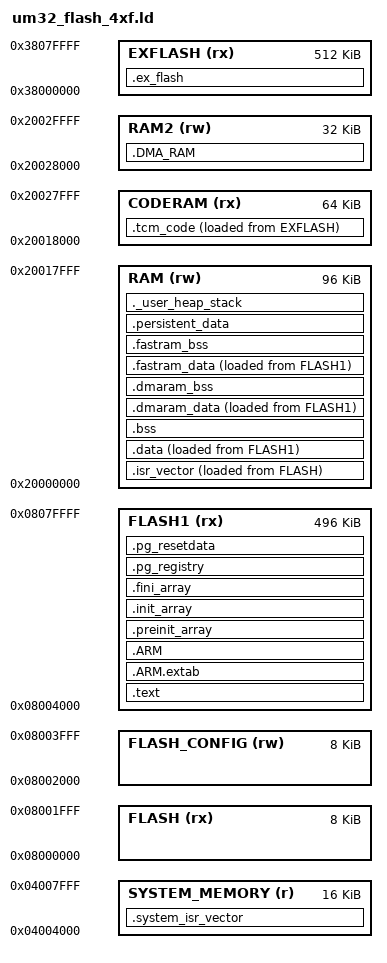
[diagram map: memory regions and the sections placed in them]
/*
*****************************************************************************
**
**  File        : um32_flash_4xf.ld
**
**  Abstract    : Linker script for UM324xF device with
**                512KByte eFLASH
**                128KByte SRAM0
**                32KByte  SRAM1
**                32KByte  SRAM2
**
*****************************************************************************
*/

/* Specify the memory areas. */
MEMORY
{
    FLASH (rx)        : ORIGIN = 0x08000000, LENGTH = 8K
    FLASH_CONFIG (rw) : ORIGIN = 0x08002000, LENGTH = 8K
    FLASH1 (rx)       : ORIGIN = 0x08004000, LENGTH = 496K
    EXFLASH (rx)      : ORIGIN = 0x38000000, LENGTH = 512K

    SYSTEM_MEMORY (r) : ORIGIN = 0x4004000, LENGTH = 16K

    RAM (rw)        : ORIGIN = 0x20000000, LENGTH = 96K
    CODERAM (rx)    : ORIGIN = 0x20018000, LENGTH = 64K
    RAM2 (rw)       : ORIGIN = 0x20028000, LENGTH = 32K
}

REGION_ALIAS("VECTAB", RAM)
REGION_ALIAS("FASTRAM", RAM)
REGION_ALIAS("STACKRAM", RAM)


/* Entry Point */
ENTRY(Reset_Handler)

/* Highest address of the user mode stack */
_Hot_Reboot_Flags_Size = 0;
_estack = ORIGIN(STACKRAM) + LENGTH(STACKRAM) - _Hot_Reboot_Flags_Size;    /* end of RAM */

/* Base address where the config is stored. */
__config_start = ORIGIN(FLASH_CONFIG);
__config_end = ORIGIN(FLASH_CONFIG) + LENGTH(FLASH_CONFIG);

/* Generate a link error if heap and stack don't fit into RAM */
_Min_Heap_Size = 0x100;       /* required amount of heap  */
_Min_Stack_Size = 0x800;      /* required amount of stack */

/* Define output sections */
SECTIONS
{
  /*
   * The ISR vector table is loaded at the beginning of the FLASH,
   * But it is linked (space reserved) at the beginning of the VECTAB region,
   * which is aliased either to FLASH or RAM.
   * When linked to RAM, the table can optionally be copied from FLASH to RAM
   * for table relocation.
   */

  _isr_vector_table_flash_base = LOADADDR(.isr_vector);
  PROVIDE (isr_vector_table_flash_base = _isr_vector_table_flash_base);

  .isr_vector :
  {
    . = ALIGN(512);
    PROVIDE (isr_vector_table_base = .);
    KEEP(*(.isr_vector)) /* Startup code */
    . = ALIGN(512);
    PROVIDE (isr_vector_table_end = .);
  } >VECTAB AT>FLASH

  /* System memory (read-only bootloader) interrupt vector */
  .system_isr_vector (NOLOAD) :
  {
    . = ALIGN(512);
    PROVIDE (system_isr_vector_table_base = .);
    KEEP(*(.system_isr_vector)) /* Bootloader code */
    . = ALIGN(512);
  } >SYSTEM_MEMORY

  /* The program code and other data goes into FLASH */
  .text :
  {
    . = ALIGN(4);
    *(.text)           /* .text sections (code) */
    *(.text*)          /* .text* sections (code) */
    *(.rodata)         /* .rodata sections (constants, strings, etc.) */
    *(.rodata*)        /* .rodata* sections (constants, strings, etc.) */
    *(.glue_7)         /* glue arm to thumb code */
    *(.glue_7t)        /* glue thumb to arm code */
    *(.eh_frame)

    KEEP (*(.init))
    KEEP (*(.fini))

    . = ALIGN(4);
    _etext = .;        /* define a global symbols at end of code */
  } >FLASH1

  .ARM.extab   : { *(.ARM.extab* .gnu.linkonce.armextab.*) } >FLASH1
    .ARM : {
      __exidx_start = .;
      *(.ARM.exidx*)
      __exidx_end = .;
    } >FLASH1

  .preinit_array     :
  {
    PROVIDE_HIDDEN (__preinit_array_start = .);
    KEEP (*(.preinit_array*))
    PROVIDE_HIDDEN (__preinit_array_end = .);
  } >FLASH1
  .init_array :
  {
    PROVIDE_HIDDEN (__init_array_start = .);
    KEEP (*(SORT(.init_array.*)))
    KEEP (*(.init_array*))
    PROVIDE_HIDDEN (__init_array_end = .);
  } >FLASH1
  .fini_array :
  {
    PROVIDE_HIDDEN (__fini_array_start = .);
    KEEP (*(.fini_array*))
    KEEP (*(SORT(.fini_array.*)))
    PROVIDE_HIDDEN (__fini_array_end = .);
  } >FLASH1
  .pg_registry :
  {
    PROVIDE_HIDDEN (__pg_registry_start = .);
    KEEP (*(.pg_registry))
    KEEP (*(SORT(.pg_registry.*)))
    PROVIDE_HIDDEN (__pg_registry_end = .);
  } >FLASH1
  .pg_resetdata :
  {
    PROVIDE_HIDDEN (__pg_resetdata_start = .);
    KEEP (*(.pg_resetdata))
    PROVIDE_HIDDEN (__pg_resetdata_end = .);
  } >FLASH1

  /* section for XIP_FLASH */
  .ex_flash :
  {
     . = ALIGN(4) ;
     KEEP (*(.ex_code))
     KEEP (*(.ex_data))
     *(.ex_code*)
     *(.ex_data*)
     . = ALIGN(4) ;
  } > EXFLASH

  /* used by the startup to initialize data */
  _sidata = LOADADDR(.data);

  /* Initialized data sections goes into RAM, load LMA copy after code */
  .data :
  {
    . = ALIGN(4);
    _sdata = .;        /* create a global symbol at data start */
    *(.data)           /* .data sections */
    *(.data*)          /* .data* sections */

    . = ALIGN(4);
    _edata = .;        /* define a global symbol at data end */
  } >RAM AT>FLASH1

  /* Uninitialized data section */
  . = ALIGN(4);
  .bss (NOLOAD) :
  {
    /* This is used by the startup in order to initialize the .bss secion */
    _sbss = .;         /* define a global symbol at bss start */
    __bss_start__ = _sbss;
    *(.bss)
    *(SORT_BY_ALIGNMENT(.bss*))
    *(COMMON)

    . = ALIGN(4);
    _ebss = .;         /* define a global symbol at bss end */
    __bss_end__ = _ebss;
  } >RAM

  /* used during startup to initialized dmaram_data */
  _sdmaram_idata = LOADADDR(.dmaram_data);

  . = ALIGN(32);
  .dmaram_data :
  {
    PROVIDE(dmaram_start = .);
    _sdmaram = .;
    _dmaram_start__ = _sdmaram;
    _sdmaram_data = .;
    *(.dmaram_data)
    *(.dmaram_data*)
    . = ALIGN(32);
    _edmaram_data = .;
  } >RAM AT >FLASH1

  . = ALIGN(32);
  .dmaram_bss (NOLOAD) :
  {
    _sdmaram_bss = .;
    __dmaram_bss_start__ = _sdmaram_bss;
    *(.dmaram_bss)
    *(SORT_BY_ALIGNMENT(.dmaram_bss*))
    . = ALIGN(32);
    _edmaram_bss = .;
    __dmaram_bss_end__ = _edmaram_bss;
  } >RAM

  . = ALIGN(32);
  .DMA_RAM (NOLOAD) :
  {
    KEEP(*(.DMA_RAM))
    PROVIDE(dmaram_end = .);
    _edmaram = .;
    _dmaram_end__ = _edmaram;
  } >RAM2

  /* Critical program code goes into CODERAM */
  /* Copy specific fast-executing code to CODERAM */
  tcm_code = LOADADDR(.tcm_code);
  .tcm_code :
  {
    . = ALIGN(4);
    tcm_code_start = .;
    *(.tcm_code)
    *(.tcm_code*)
    . = ALIGN(4);
    tcm_code_end = .;
  } >CODERAM AT>EXFLASH

  /* used during startup to initialized fastram_data */
  _sfastram_idata = LOADADDR(.fastram_data);

  /* Initialized FAST_DATA section for unsuspecting developers */
  .fastram_data :
  {
    . = ALIGN(4);
    _sfastram_data = .;        /* create a global symbol at data start */
    *(.fastram_data)           /* .data sections */
    *(.fastram_data*)          /* .data* sections */

    . = ALIGN(4);
    _efastram_data = .;        /* define a global symbol at data end */
  } >FASTRAM AT>FLASH1

  . = ALIGN(4);
  .fastram_bss (NOLOAD) :
  {
    __fastram_bss_start__ = .;
    *(.fastram_bss)
    *(SORT_BY_ALIGNMENT(.fastram_bss*))
    . = ALIGN(4);
    __fastram_bss_end__ = .;
  } >FASTRAM

  .persistent_data (NOLOAD) :
  {
    __persistent_data_start__ = .;
    *(.persistent_data)
    . = ALIGN(4);
    __persistent_data_end__ = .;
  } >RAM

  /* User_heap_stack section, used to check that there is enough RAM left */
  _heap_stack_end = ORIGIN(STACKRAM) + LENGTH(STACKRAM) - _Hot_Reboot_Flags_Size;
  _heap_stack_begin = _heap_stack_end - _Min_Stack_Size  - _Min_Heap_Size;
  . = _heap_stack_begin;
  ._user_heap_stack :
  {
    . = ALIGN(4);
    PROVIDE ( end = . );
    PROVIDE ( _end = . );
    . = . + _Min_Heap_Size;
    . = . + _Min_Stack_Size;
    . = ALIGN(4);
  } >STACKRAM = 0xa5

  /* Remove information from the standard libraries */
  /DISCARD/ :
  {
    libc.a ( * )
    libm.a ( * )
    libgcc.a ( * )
  }

  .ARM.attributes 0 : { *(.ARM.attributes) }
}

